AUTOSAR XML (schema 4-0-3)
package /ComponentTypes
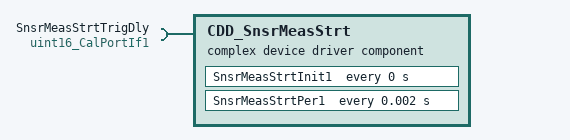
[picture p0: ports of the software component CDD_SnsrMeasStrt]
  complex device driver sw component type CDD_SnsrMeasStrt
    require port SnsrMeasStrtTrigDly: parameter-require-com-spec{init-value=356, parameter=Val}, required-interface=uint16_CalPortIf1  # Trigger Delay - 2ms Jitter control
    behavior CDD_SnsrMeasStrt_InternalBehavior
      ar-typed-per-instance-memorys:
        data TqMsgTrigCnt: sw-calibration-access=READ-ONLY, type=uint32  # Captures how many timer trigger happen
      timing event CDD_SnsrMeasStrt_InitEvent: start-on-event=SnsrMeasStrtInit1, period=0
      timing event TMT_SnsrMeasStrtPer1: start-on-event=SnsrMeasStrtPer1, period=0.002
      runnable SnsrMeasStrtInit1  # Timer Peripheral Initialization
      runnable SnsrMeasStrtPer1  # Calculate the Timer Value for Trigger
  swc implementation CDD_SnsrMeasStrt_Implementation: behavior=CDD_SnsrMeasStrt_InternalBehavior
    code-descriptors:
      code Default: artifact-descriptors=autosar-engineering-object={short-label=Default, category=SWSRC}
